VERSION ""

NS_ :

BS_:

BU_:

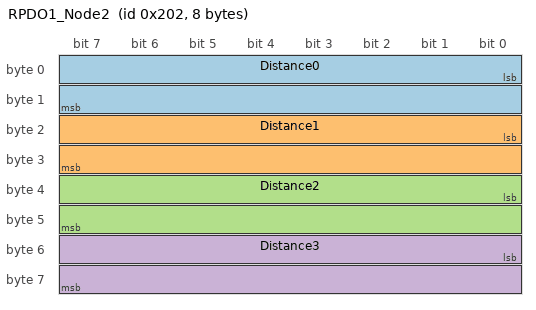
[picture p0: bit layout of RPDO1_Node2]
BO_ 514 RPDO1_Node2: 8 Vector__XXX
	SG_ Distance0 : 0|16@1+ (1,0) [0|65535] "cm" Vector__XXX
	SG_ Distance1 : 16|16@1+ (1,0) [0|65535] "cm" Vector__XXX
	SG_ Distance2 : 32|16@1+ (1,0) [0|65535] "cm" Vector__XXX
	SG_ Distance3 : 48|16@1+ (1,0) [0|65535] "cm" Vector__XXX

CM_ BO_ 514 "Sends freespace info from Orin to Pixhawk";
CM_ SG_ 514 Distance0 "0 - invalid, 65535 - no detection";
BA_DEF_ SG_  "SPN" INT 0 524287;
BA_DEF_ BO_  "VFrameFormat" ENUM  "StandardCAN","ExtendedCAN","reserved","J1939PG";
BA_DEF_  "DatabaseVersion" STRING ;
BA_DEF_  "BusType" STRING ;
BA_DEF_  "ProtocolType" STRING ;
BA_DEF_  "DatabaseCompiler" STRING ;
BA_DEF_DEF_  "SPN" 0;
BA_DEF_DEF_  "VFrameFormat" "J1939PG";
BA_DEF_DEF_  "DatabaseVersion" "DEMO PLUS";
BA_DEF_DEF_  "BusType" "";
BA_DEF_DEF_  "ProtocolType" "";
BA_DEF_DEF_  "DatabaseCompiler" "";
BA_ "ProtocolType" "J1939";
BA_ "BusType" "CAN";
BA_ "DatabaseCompiler" "CSS ELECTRONICS (WWW.CSSELECTRONICS.COM)";
BA_ "DatabaseVersion" "1.0.0";
BA_ "SPN" SG_ 514 Distance0 190;
